VERSION ""

NS_ :

BS_:

BU_: XXX

BO_ 85 EPB: 8 XXX
 SG_ EPB_ACTIVE : 40|1@1+ (1,0) [0|1] "" XXX

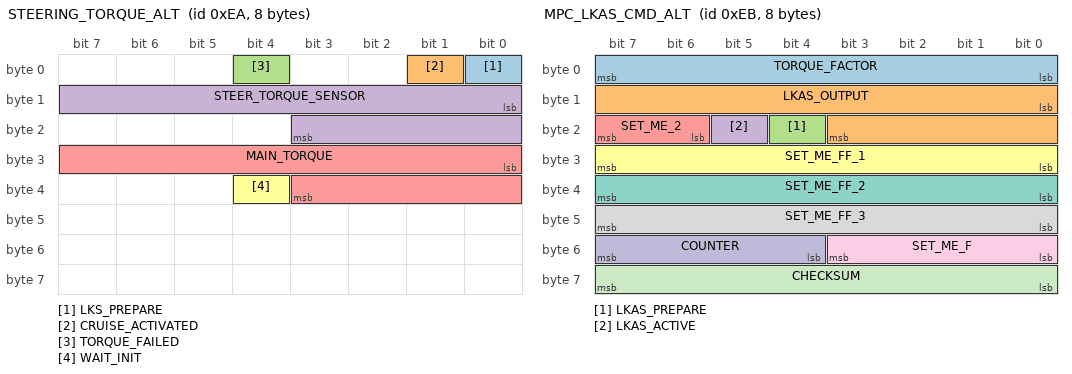
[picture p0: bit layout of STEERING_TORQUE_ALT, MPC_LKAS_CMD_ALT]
BO_ 234 STEERING_TORQUE_ALT: 8 XXX
 SG_ LKS_PREPARE : 0|1@1+ (1,0) [0|1] "" XXX
 SG_ CRUISE_ACTIVATED : 1|1@1+ (1,0) [0|1] "" XXX
 SG_ TORQUE_FAILED : 4|1@1+ (1,0) [0|1] "" XXX
 SG_ STEER_TORQUE_SENSOR : 8|12@1- (1,0) [0|4095] "" XXX
 SG_ MAIN_TORQUE : 24|12@1+ (0.15,-316) [0|4095] "" XXX
 SG_ WAIT_INIT : 36|1@1+ (1,0) [0|1] "" XXX

BO_ 235 MPC_LKAS_CMD_ALT: 8 XXX
 SG_ TORQUE_FACTOR : 0|8@1+ (1,0) [0|255] "" XXX
 SG_ LKAS_OUTPUT : 8|12@1- (0.15,0) [0|4095] "" XXX
 SG_ LKAS_PREPARE : 20|1@1+ (1,0) [0|1] "" XXX
 SG_ LKAS_ACTIVE : 21|1@1+ (1,0) [0|1] "" XXX
 SG_ SET_ME_2 : 22|2@1+ (1,0) [0|1] "" XXX
 SG_ SET_ME_FF_1 : 24|8@1+ (1,0) [0|255] "" XXX
 SG_ SET_ME_FF_2 : 32|8@1+ (1,0) [0|255] "" XXX
 SG_ SET_ME_FF_3 : 40|8@1+ (1,0) [0|255] "" XXX
 SG_ SET_ME_F : 48|4@1+ (1,0) [0|15] "" XXX
 SG_ COUNTER : 55|4@0+ (1,0) [0|15] "" XXX
 SG_ CHECKSUM : 63|8@0+ (1,0) [0|255] "" XXX

BO_ 269 ECM: 8 XXX
 SG_ ENG_RPM : 0|16@1+ (0.25,0) [0|255] "" XXX
 SG_ GAS_PEDAL : 40|8@1+ (0.00392,0) [0|255] "" XXX

/* DRIVER_EPS_TORQUE could just be STEER_RATE */
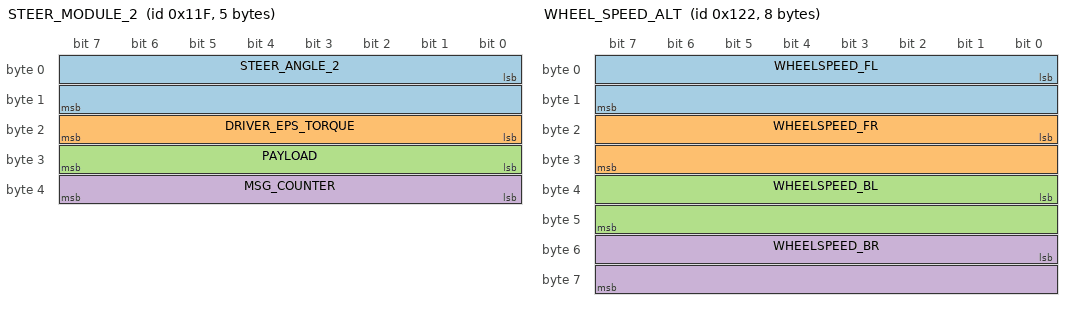
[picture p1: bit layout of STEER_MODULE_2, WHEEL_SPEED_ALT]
BO_ 287 STEER_MODULE_2: 5 XXX
 SG_ STEER_ANGLE_2 : 0|16@1- (0.1,0) [0|65535] "" XXX
 SG_ DRIVER_EPS_TORQUE : 16|8@1+ (1,0) [0|255] "" XXX
 SG_ PAYLOAD : 24|8@1+ (1,0) [0|255] "" XXX
 SG_ MSG_COUNTER : 32|8@1+ (1,0) [0|255] "" XXX

BO_ 289 ESC: 8 XXX
 SG_ VEHICLE_SPEED : 0|12@1+ (0.0725,0) [0|4095] "" XXX

BO_ 290 WHEEL_SPEED_ALT: 8 XXX
 SG_ WHEELSPEED_FL : 0|16@1+ (0.1,0) [0|65535] "" XXX
 SG_ WHEELSPEED_FR : 16|16@1+ (0.1,0) [0|65535] "" XXX
 SG_ WHEELSPEED_BL : 32|16@1+ (0.1,0) [0|65535] "" XXX
 SG_ WHEELSPEED_BR : 48|16@1+ (0.1,0) [0|65535] "" XXX

BO_ 291 IPB: 8 XXX
 SG_ BRAKE_PRESSED : 43|1@0+ (1,0) [0|1] "" XXX

BO_ 301 BRAKE_PRESSED: 8 XXX
 SG_ BRAKE_PRESSED : 8|1@1+ (1,0) [0|1] "" XXX

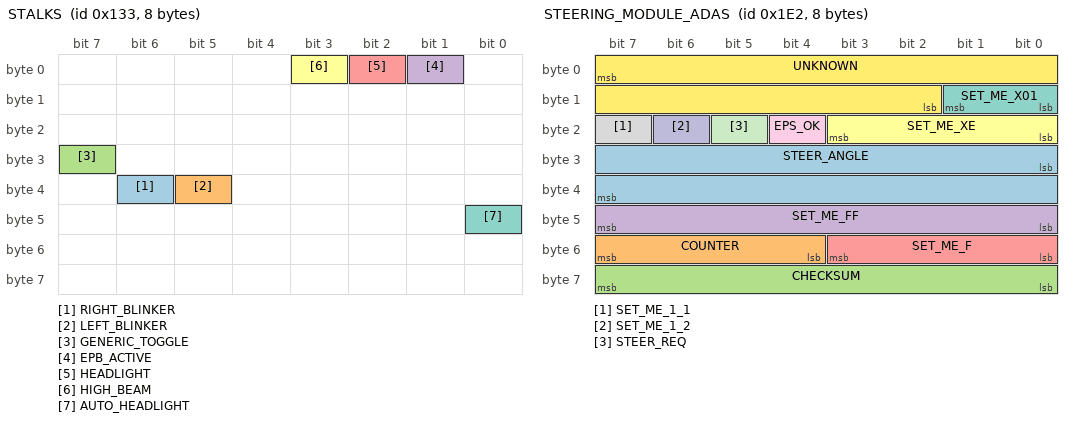
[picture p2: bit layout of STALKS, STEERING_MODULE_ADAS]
BO_ 307 STALKS: 8 XXX
 SG_ RIGHT_BLINKER : 38|1@0+ (1,0) [0|1] "" XXX
 SG_ LEFT_BLINKER : 37|1@0+ (1,0) [0|1] "" XXX
 SG_ GENERIC_TOGGLE : 31|1@0+ (1,0) [0|1] "" XXX
 SG_ EPB_ACTIVE : 1|1@1+ (1,0) [0|1] "" XXX
 SG_ HEADLIGHT : 2|1@1+ (1,0) [0|1] "" XXX
 SG_ HIGH_BEAM : 3|1@1+ (1,0) [0|1] "" XXX
 SG_ AUTO_HEADLIGHT : 40|1@0+ (1,0) [0|1] "" XXX

BO_ 482 STEERING_MODULE_ADAS: 8 XXX
 SG_ STEER_ANGLE : 24|16@1- (0.1,0) [0|255] "" XXX
 SG_ COUNTER : 55|4@0+ (1,0) [0|15] "" XXX
 SG_ CHECKSUM : 63|8@0+ (1,0) [0|255] "" XXX
 SG_ SET_ME_FF : 47|8@0+ (1,0) [0|255] "" XXX
 SG_ SET_ME_F : 48|4@1+ (1,0) [0|15] "" XXX
 SG_ SET_ME_XE : 16|4@1+ (1,0) [0|15] "" XXX
 SG_ SET_ME_X01 : 8|2@1+ (1,0) [0|3] "" XXX
 SG_ SET_ME_1_1 : 23|1@0+ (1,0) [0|1] "" XXX
 SG_ EPS_OK : 20|1@0+ (1,0) [0|1] "" XXX
 SG_ SET_ME_1_2 : 22|1@0+ (1,0) [0|3] "" XXX
 SG_ STEER_REQ : 21|1@0+ (1,0) [0|1] "" XXX
 SG_ UNKNOWN : 7|14@0- (1,0) [0|65535] "" XXX

BO_ 455 STEER_ANGLE_ALT: 8 XXX
 SG_ STEER_ANGLE : 0|16@1- (0.1,0) [0|4095] "" XXX
 SG_ STEER_RATE : 16|8@1+ (4,0) [0|255] "" XXX

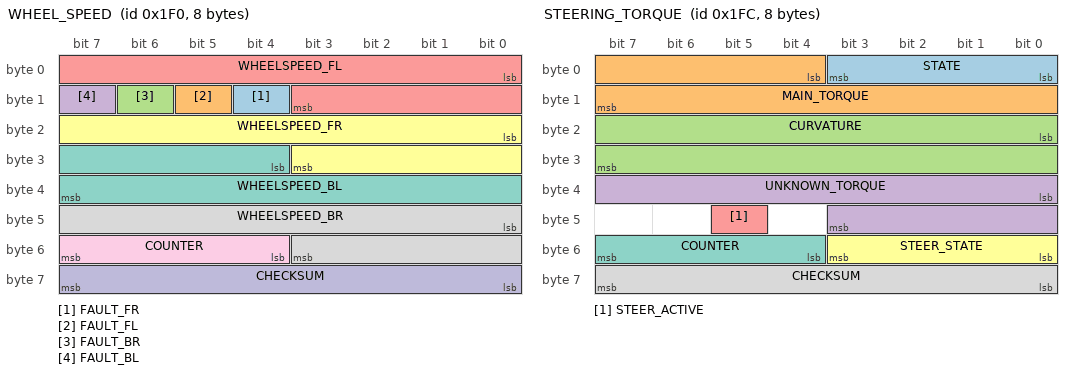
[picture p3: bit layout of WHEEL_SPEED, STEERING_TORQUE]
BO_ 496 WHEEL_SPEED: 8 XXX
 SG_ FAULT_FR : 12|1@1+ (1,0) [0|1] "" XXX
 SG_ FAULT_FL : 13|1@1+ (1,0) [0|1] "" XXX
 SG_ FAULT_BR : 14|1@1+ (1,0) [0|1] "" XXX
 SG_ FAULT_BL : 15|1@1+ (1,0) [0|1] "" XXX
 SG_ WHEELSPEED_FL : 0|12@1+ (0.1,0) [0|281.4625] "km/h" XXX
 SG_ WHEELSPEED_FR : 16|12@1+ (0.1,0) [0|281.4625] "km/h" XXX
 SG_ WHEELSPEED_BL : 28|12@1+ (0.1,0) [0|281.4625] "km/h" XXX
 SG_ WHEELSPEED_BR : 40|12@1+ (0.1,0) [0|281.4625] "km/h" XXX
 SG_ COUNTER : 55|4@0+ (1,0) [0|15] "" XXX
 SG_ CHECKSUM : 63|8@0+ (1,0) [0|255] "" XXX

BO_ 508 STEERING_TORQUE: 8 XXX
 SG_ STATE : 0|4@1+ (1,0) [0|15] "" XXX
 SG_ MAIN_TORQUE : 4|12@1- (0.1,0) [0|15] "Nm" XXX
 SG_ CURVATURE : 16|16@1- (0.1,0) [0|65535] "" XXX
 SG_ UNKNOWN_TORQUE : 32|12@1- (1,0) [0|255] "" XXX
 SG_ STEER_ACTIVE : 45|1@1+ (1,0) [0|1] "" XXX
 SG_ STEER_STATE : 51|4@0+ (1,0) [0|1] "" XXX
 SG_ COUNTER : 55|4@0+ (1,0) [0|15] "" XXX
 SG_ CHECKSUM : 63|8@0+ (1,0) [0|255] "" XXX

BO_ 522 ENGINE_RPM: 8 XXX
 SG_ ENG_RPM : 31|8@0+ (1,0) [0|255] "" XXX

BO_ 523 ENGINE_GAUGE: 8 XXX
 SG_ ENG_RPM : 15|8@0+ (12,0) [0|0] "" XXX

BO_ 536 EPB_NG: 8 XXX
 SG_ EPB_ACTIVE : 0|2@1+ (1,0) [0|3] "" XXX
 SG_ EPB_STATUS : 9|3@1+ (1,0) [0|7] "" XXX

BO_ 544 PEDAL_PRESSED: 8 XXX
 SG_ PEDAL_PRESSED_ACTIVE_LOW : 12|1@0+ (1,0) [0|1] "" XXX

BO_ 546 YAW_SENSOR: 8 XXX
 SG_ YAW_RATE : 0|12@1+ (0.002132603,-2.094216146) [0|4095] "" XXX
 SG_ YAW_OFFSET : 12|12@1+ (0.002132603,-0.130088783) [0|4095] "" XXX

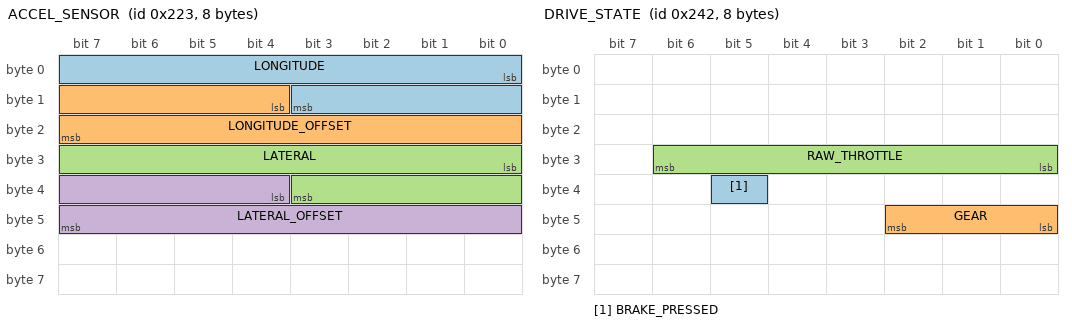
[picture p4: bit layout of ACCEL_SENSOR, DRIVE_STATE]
BO_ 547 ACCEL_SENSOR: 8 XXX
 SG_ LONGITUDE : 0|12@1- (0.027126736,-21.592881856) [-2848|1247] "" XXX
 SG_ LONGITUDE_OFFSET : 12|12@1+ (0.027126736,-21.592881856) [0|4095] "" XXX
 SG_ LATERAL : 24|12@1- (0.027126736,-21.592881856) [-2848|1247] "" XXX
 SG_ LATERAL_OFFSET : 36|12@1+ (0.027126736,-21.592881856) [0|4095] "" XXX

BO_ 578 DRIVE_STATE: 8 XXX
 SG_ BRAKE_PRESSED : 37|1@0+ (1,0) [0|1] "" XXX
 SG_ GEAR : 40|3@1+ (1,0) [0|7] "" XXX
 SG_ RAW_THROTTLE : 30|7@0+ (1,0) [0|127] "" XXX

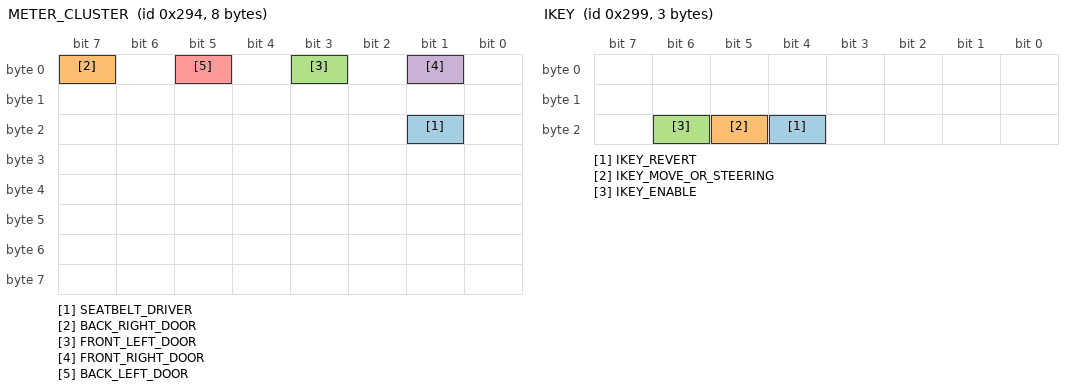
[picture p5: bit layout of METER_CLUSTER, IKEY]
BO_ 660 METER_CLUSTER: 8 XXX
 SG_ SEATBELT_DRIVER : 17|1@0+ (1,0) [0|1] "" XXX
 SG_ BACK_RIGHT_DOOR : 7|1@0+ (1,0) [0|1] "" XXX
 SG_ FRONT_LEFT_DOOR : 3|1@0+ (1,0) [0|1] "" XXX
 SG_ FRONT_RIGHT_DOOR : 1|1@1+ (1,0) [0|511] "" XXX
 SG_ BACK_LEFT_DOOR : 5|1@1+ (1,0) [0|511] "" XXX

BO_ 665 IKEY: 3 XXX
 SG_ IKEY_REVERT : 20|1@1+ (1,0) [0|1] "" XXX
 SG_ IKEY_MOVE_OR_STEERING : 21|1@1+ (1,0) [0|1] "" XXX
 SG_ IKEY_ENABLE : 22|1@1+ (1,0) [0|1] "" XXX

BO_ 790 LKAS_HUD_ADAS: 8 XXX
CM_ BO_ 790 "Openpilot code packs continuous SET_ME_XFF + TSR_STATUS into one lkas_hud_status_passthrough chunk in BYD carstate/controller.";
 SG_ HMA : 4|5@0+ (1,0) [0|7] "" XXX
 SG_ LEFT_LANE_VISIBLE : 5|1@0+ (1,0) [0|1] "" XXX
 SG_ LSS_STATE : 7|2@0+ (1,0) [0|1] "" XXX
 SG_ PT3 : 8|2@1+ (1,0) [0|3] "" XXX
 SG_ HAND_ON_WHEEL_WARNING : 10|1@0+ (1,0) [0|1] "" XXX
 SG_ PT2 : 11|5@1+ (1,0) [0|31] "" XXX
 SG_ SET_ME_XFF : 23|8@0+ (1,0) [0|255] "" XXX
 SG_ TSR_STATUS : 31|3@0+ (1,0) [0|7] "" XXX
 SG_ SET_ME_1_2 : 32|1@0+ (1,0) [0|1] "" XXX
 SG_ PT5 : 33|2@1+ (1,0) [0|3] "" XXX
 SG_ RIGHT_LANE_VISIBLE : 35|1@0+ (1,0) [0|1] "" XXX
 SG_ STEER_ACTIVE_ACTIVE_LOW : 36|1@0+ (1,0) [0|1] "" XXX
 SG_ LKAS_ENABLED : 37|1@0+ (1,0) [0|1] "" XXX
 SG_ PT4 : 39|2@0+ (1,0) [0|3] "" XXX
 SG_ TSR : 47|8@0+ (1,0) [0|255] "" XXX
 SG_ SETTINGS : 48|4@1+ (1,0) [0|15] "" XXX
 SG_ COUNTER : 55|4@0+ (1,0) [0|15] "" XXX
 SG_ CHECKSUM : 63|8@0+ (1,0) [0|255] "" XXX

BO_ 813 ACC_HUD_ADAS: 8 XXX
 SG_ SET_SPEED : 0|9@1+ (0.5,0) [0|255.5] "" XXX
 SG_ HAS_LEAD : 9|1@1+ (1,0) [0|1] "" XXX
 SG_ SET_DISTANCE : 10|3@1+ (1,0) [0|7] "" XXX
 SG_ LEAD_DISTANCE : 13|3@1+ (1,0) [0|7] "" XXX
 SG_ AEB : 16|1@1+ (1,0) [0|1] "" XXX
 SG_ FCW : 17|1@1+ (1,0) [0|1] "" XXX
 SG_ SET_ME_1 : 18|1@1+ (1,0) [0|1] "" XXX
 SG_ ACC_ON2 : 19|1@0+ (1,0) [0|1] "" XXX
 SG_ ACC_CONTROLLABLE_AND_ON : 20|1@1+ (1,0) [0|1] "" XXX
 SG_ OVERRIDE : 21|1@1+ (1,0) [0|1] "" XXX
 SG_ ACC_ON1 : 22|1@0+ (1,0) [0|1] "" XXX
 SG_ TOO_CLOSE : 23|1@0+ (1,0) [0|1] "" XXX
 SG_ SET_ME_1_1 : 24|3@1+ (1,0) [0|1] "" XXX
 SG_ NOTIFY : 27|5@1+ (1,0) [0|127] "" XXX
 SG_ ERROR : 32|4@1+ (1,0) [0|15] "" XXX
 SG_ SET_ME_XFF : 36|8@1+ (1,0) [0|4095] "" XXX
 SG_ CRUISE_STATE : 44|4@1+ (1,0) [0|15] "" XXX
 SG_ SET_ME_XF : 55|4@0+ (1,0) [0|15] "" XXX
 SG_ COUNTER : 51|4@0+ (1,0) [0|15] "" XXX
 SG_ CHECKSUM : 63|8@0+ (1,0) [0|255] "" XXX

BO_ 814 ACC_CMD: 8 XXX
 SG_ ACCEL_CMD : 0|8@1+ (0.05,-5) [-5|7.75] "m/s2" XXX
 SG_ COUNTER : 51|4@0+ (1,0) [0|15] "" XXX
 SG_ CHECKSUM : 63|8@0+ (1,0) [0|255] "" XXX
 SG_ SET_ME_25_1 : 10|6@1+ (1,0) [0|255] "" XXX
 SG_ SET_ME_25_2 : 18|6@1+ (1,0) [0|255] "" XXX
 SG_ ACC_ON_1 : 9|1@0+ (1,0) [0|1] "" XXX
 SG_ ACC_ON_2 : 17|1@0+ (1,0) [0|1] "" XXX
 SG_ SET_ME_XF : 55|4@0+ (1,0) [0|15] "" XXX
 SG_ ACC_OVERRIDE_OR_STANDSTILL : 45|1@0+ (1,0) [0|1] "" XXX
 SG_ ACC_CONTROLLABLE_AND_ON : 44|1@0+ (1,0) [0|1] "" XXX
 SG_ STANDSTILL_STATE : 40|1@0+ (1,0) [0|1] "" XXX
 SG_ SET_ME_X8 : 31|4@0+ (1,0) [0|255] "" XXX
 SG_ CMD_REQ_ACTIVE_LOW : 36|1@0+ (1,0) [0|255] "" XXX
 SG_ ACC_REQ_NOT_STANDSTILL : 43|1@0+ (1,0) [0|1] "" XXX
 SG_ STANDSTILL_RESUME : 39|1@0+ (1,0) [0|1] "" XXX
 SG_ SET_ME_1 : 38|1@0+ (1,0) [0|1] "" XXX
 SG_ ACCEL_FACTOR : 32|4@1+ (1,0) [0|15] "" XXX
 SG_ DECEL_FACTOR : 24|4@1+ (1,0) [0|15] "" XXX
 SG_ ENGAGE_BIT : 47|1@0+ (1,0) [0|1] "" XXX

BO_ 815 ACC_AEB: 8 XXX
 SG_ PAYLOAD : 0|48@1+ (1,0) [0|4.5035996273705e+15] "" XXX
 SG_ SETME_0xF : 55|4@0+ (1,0) [0|15] "" XXX

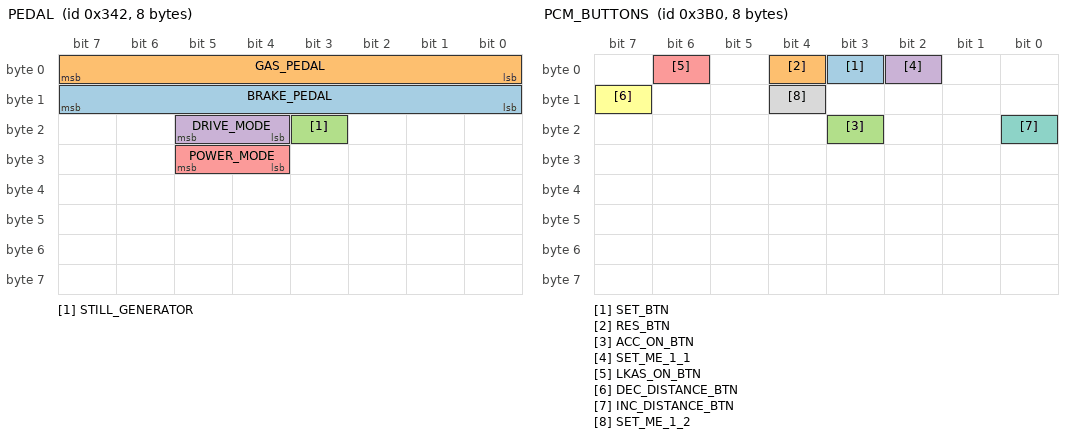
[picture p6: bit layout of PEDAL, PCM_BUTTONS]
BO_ 834 PEDAL: 8 XXX
 SG_ BRAKE_PEDAL : 8|8@1+ (0.01,0) [0|255] "" XXX
 SG_ GAS_PEDAL : 0|8@1+ (0.01,0) [0|255] "" XXX
 SG_ STILL_GENERATOR : 19|1@1+ (1,0) [0|1] "" XXX
 SG_ DRIVE_MODE : 20|2@1+ (1,0) [0|255] "" XXX
 SG_ POWER_MODE : 28|2@1+ (1,0) [0|1] "" XXX

BO_ 926 GAUGE_SPEED: 8 XXX
 SG_ GAUGE_SPEED : 8|8@1+ (1,0) [0|255] "" XXX

BO_ 944 PCM_BUTTONS: 8 XXX
 SG_ SET_BTN : 3|1@0+ (1,0) [0|1] "" XXX
 SG_ RES_BTN : 4|1@0+ (1,0) [0|1] "" XXX
 SG_ ACC_ON_BTN : 19|1@0+ (1,0) [0|1] "" XXX
 SG_ SET_ME_1_1 : 2|1@0+ (1,0) [0|1] "" XXX
 SG_ LKAS_ON_BTN : 6|1@0+ (1,0) [0|1] "" XXX
 SG_ DEC_DISTANCE_BTN : 15|1@0+ (1,0) [0|1] "" XXX
 SG_ INC_DISTANCE_BTN : 16|1@0+ (1,0) [0|1] "" XXX
 SG_ SET_ME_1_2 : 12|1@0+ (1,0) [0|1] "" XXX

BO_ 1048 BSM: 8 XXX
 SG_ LEFT_APPROACH : 23|1@0+ (1,0) [0|1] "" XXX
 SG_ RIGHT_APPROACH : 17|1@0+ (1,0) [0|1] "" XXX

BO_ 692 ADAS2: 8 XXX

BO_ 843 ADAS4: 8 XXX

BO_ 1074 ADAS6: 8 XXX

/* USED BY OTHER BYDs */
BO_ 848 RADAR_UNUSED_0: 8 XXX

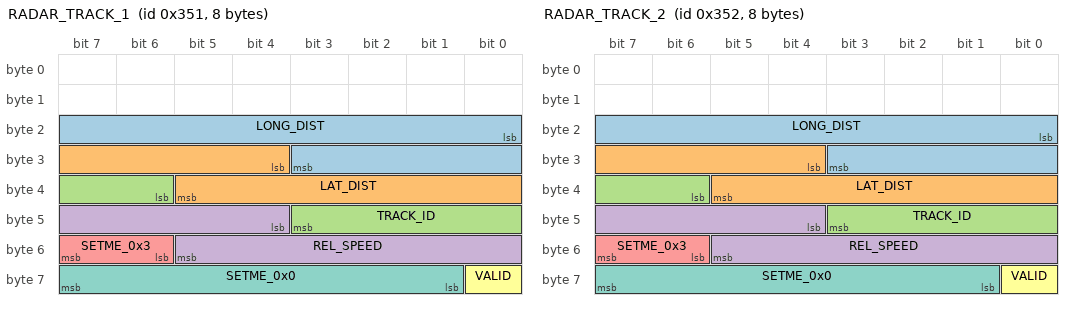
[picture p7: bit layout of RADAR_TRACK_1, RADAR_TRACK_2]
BO_ 849 RADAR_TRACK_1: 8 XXX
 SG_ LONG_DIST : 16|12@1- (0.06,-4) [-61.44|61.41] "m" XXX
 SG_ LAT_DIST : 28|10@1+ (0.05,-25.6) [-15.36|15.33] "m" XXX
 SG_ TRACK_ID : 38|6@1+ (1,0) [0|63] "" XXX
 SG_ REL_SPEED : 44|10@1+ (1,-512) [-512|511] "km/s" XXX
 SG_ SETME_0x3 : 54|2@1+ (1,0) [0|3] "" XXX
 SG_ VALID : 56|1@0+ (1,0) [0|1] "" XXX
 SG_ SETME_0x0 : 57|7@1+ (1,0) [0|127] "" XXX

BO_ 850 RADAR_TRACK_2: 8 XXX
 SG_ LONG_DIST : 16|12@1- (0.06,-4) [-61.44|61.41] "m" XXX
 SG_ LAT_DIST : 28|10@1+ (-0.05,-25.6) [-15.36|15.33] "m" XXX
 SG_ TRACK_ID : 38|6@1+ (1,0) [0|63] "" XXX
 SG_ REL_SPEED : 44|10@1+ (1,-512) [-512|511] "km/s" XXX
 SG_ SETME_0x3 : 54|2@1+ (1,0) [0|3] "" XXX
 SG_ VALID : 56|1@0+ (1,0) [0|1] "" XXX
 SG_ SETME_0x0 : 57|7@1+ (1,0) [0|127] "" XXX

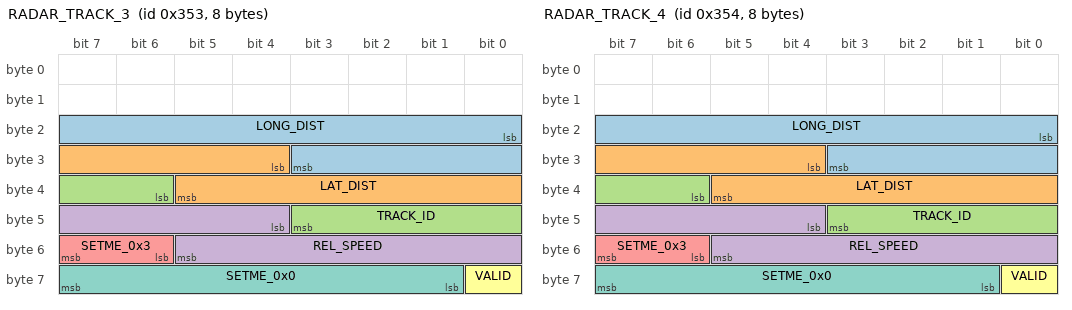
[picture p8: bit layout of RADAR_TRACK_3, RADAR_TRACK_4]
BO_ 851 RADAR_TRACK_3: 8 XXX
 SG_ LONG_DIST : 16|12@1- (0.06,-4) [-61.44|61.41] "m" XXX
 SG_ LAT_DIST : 28|10@1+ (0.05,-25.6) [-15.36|15.33] "m" XXX
 SG_ TRACK_ID : 38|6@1+ (1,0) [0|63] "" XXX
 SG_ REL_SPEED : 44|10@1+ (1,-512) [-512|511] "km/s" XXX
 SG_ SETME_0x3 : 54|2@1+ (1,0) [0|3] "" XXX
 SG_ VALID : 56|1@0+ (1,0) [0|1] "" XXX
 SG_ SETME_0x0 : 57|7@1+ (1,0) [0|127] "" XXX

BO_ 852 RADAR_TRACK_4: 8 XXX
 SG_ LONG_DIST : 16|12@1- (0.06,-4) [-61.44|61.41] "m" XXX
 SG_ LAT_DIST : 28|10@1+ (0.05,-25.6) [-15.36|15.33] "m" XXX
 SG_ TRACK_ID : 38|6@1+ (1,0) [0|63] "" XXX
 SG_ REL_SPEED : 44|10@1+ (1,-512) [-512|511] "km/s" XXX
 SG_ SETME_0x3 : 54|2@1+ (1,0) [0|3] "" XXX
 SG_ VALID : 56|1@0+ (1,0) [0|1] "" XXX
 SG_ SETME_0x0 : 57|7@1+ (1,0) [0|127] "" XXX

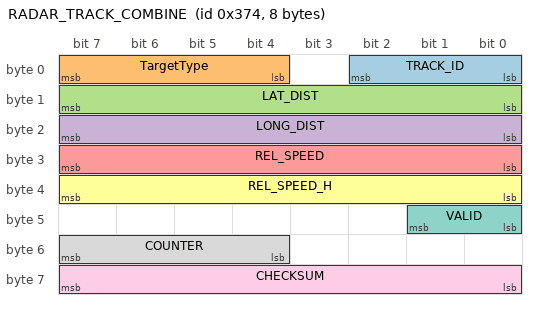
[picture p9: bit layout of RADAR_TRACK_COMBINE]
BO_ 884 RADAR_TRACK_COMBINE: 8 XXX
 SG_ TRACK_ID : 0|3@1+ (1,0) [0|7] "bit" XXX
 SG_ TargetType : 4|4@1+ (1,0) [0|8] "bit" XXX
 SG_ LAT_DIST : 8|8@1+ (0.1,-12) [-100|100] "bit" XXX
 SG_ LONG_DIST : 16|8@1+ (1,-100) [-100|100] "bit" XXX
 SG_ REL_SPEED : 24|8@1+ (1,0) [0|254] "km/h" XXX
 SG_ REL_SPEED_H : 32|8@1+ (1,0) [0|254] "km/h" XXX
 SG_ VALID : 40|2@1+ (1,0) [0|3] "bit" XXX
 SG_ COUNTER : 55|4@0+ (1,0) [0|15] "" XXX
 SG_ CHECKSUM : 63|8@0+ (1,0) [0|255] "" XXX

VAL_ 578 GEAR 4 "D" 2 "R" 1 "P" ;
VAL_ 813 SET_DISTANCE 8 "4bar" 4 "3bar" 2 "2bar" 1 "1bar" ;
VAL_ 813 NOTIFY 4 "OVERRIDE" 3 "ENGAGE" 2 "DISENGAGE" 7 "ACC_ON" 8 "ACC_OFF" 0 "NONE";
VAL_ 813 CRUISE_STATE 0 "OFF" 1 "Passive" 2 "StandBy" 3 "Active" 4 "BrakeOnly" 5 "Override" 6 "StandStillActive" 7 "StandStillWait" 8 "Failure" 9 "PermanentFailure";

CM_ SG_ 482 EPS_OK "Crosscheck 2026-08 vs qzwf/opendbc's independent RE of this same message (STEERING_MODULE_ADAS, bit 20): qzwf calls this bit STEER_REQ_ACTIVE_LOW (an inverse mirror of STEER_REQ at bit 21), not an EPS health flag. Every other signal in this message (STEER_ANGLE, COUNTER, CHECKSUM, STEER_REQ, and all SET_ME_* constants) matches qzwf's layout bit-for-bit. This bit feeds lkas_healthy in opendbc/car/byd/cam_lka/carstate.py - unresolved without a local capture, not changed here. See docs/BYD_ATTO3_COMMUNITY_LINEAGE.md.";
CM_ SG_ 814 ACCEL_CMD "CORRECTED 2026-09-21: was (1,-100) raw, with opendbc/car/byd/values.py applying ACCEL_MULT=26 on top, which put 1.30x the requested acceleration on the wire. Now carries the capture-derived scale directly, matching BYD_Atto3/DBC/byd_atto3.dbc's MPC_AccelerationCmd (0|8, x0.05, -5). Evidence: create_accel_command's +30 raw-count clip decodes to exactly +1.50 m/s2, the ceiling BYD_Atto3's COMMA-device captures recorded, and -80 to exactly -4.00; BYD_Atto3/DOC/jerk_brake_summary.md finds comfort/jerk values in 0.05 steps across every capture. qzwf/opendbc uses a third value (x16.67) and explicitly disclaims it as inferred, keeping ACC_CMD out of its TX allowlist. Raw TX envelope unchanged (raw 20..130); bench-validate before hardware use. See docs/BYD_ATTO3_QZWF_REFERENCE_PORT.md.";
CM_ BO_ 496 "DISPUTED 2026-09-21: this fork decodes WHEEL_SPEED as four 12-bit wheels at x0.1 plus fault bits 12-15. Two independent lineages decode the same frame as a SINGLE 16-bit speed at 0|16@1+ - BYD_Atto3/DBC/byd_atto3.dbc's ESP_VehicleSpeed (x1/14 km/h per count, from local CANape captures) and qzwf/opendbc's WHEELSPEED_CLEAN (x0.1, unused by their carstate). qzwf reads per-wheel speed from 0x122 instead and corrects x0.1 by 40/53 after measuring raw values ~32.5% high against the odometer, landing on 0.0755 - within 5.7% of byd_atto3.dbc's 1/14 = 0.0714, and both well below the x0.1 used here. carstate.parse_wheel_speeds, radar_interface and safety/modes/byd.h's UPDATE_VEHICLE_SPEED all read this frame, so vEgo and the speed the angle-rate lookup interpolates against are affected. Unresolved without a local GPS or odometer run - structure and scale both unchanged here pending one.";
CM_ SG_ 290 WHEELSPEED_BR "CROSSCHECK 2026-09-21: qzwf/opendbc declares this field identically (48|16@1+ x0.1) and then measured that it is wrong - 'byte 7 is a constant status byte (0x41), NOT the high byte of the wheel speed' - and derives rear-right from the other three wheels instead. Nothing in this fork reads WHEEL_SPEED_ALT today. Left as-is pending a local capture rather than guessing the real width. See docs/BYD_ATTO3_QZWF_REFERENCE_PORT.md.";
CM_ SG_ 790 SET_ME_XFF "DISPUTED 2026-09-21: bits 16-23 are not a constant. byd_han_dmev_2020.dbc (same address, ACC_MPC_STATE) and BYD_Atto3/DBC/byd_atto3.dbc both place a signed 11-bit LKAS_Output / MPC_LkasOutput at 16|11 here, with LKAS_ReqPrepare at 27 and LKAS_Active at 28 - and safety/modes/byd.h's mpc_lka path decodes exactly those bits as desired_torque. cam_lka/carstate.py reads this byte into lkas_hud_status_passthrough and create_lkas_hud writes it back out, so this fork is round-tripping the low byte of the camera's LKA torque output as filler. byd_atto3.dbc's CM_ SG_ 482 CONST_0xFF_B5 records qzwf/opendbc finding that treating a camera-derived field in the steering frame as don't-care silently killed their car's stock ADAS. qzwf's own 0x316 defines nothing in this region, so this is unresolved - not changed here.";
CM_ SG_ 482 UNKNOWN "CROSSCHECK 2026-09-21: this 14-bit field plus SET_ME_X01 and SET_ME_XE cover bits 0-19, which BYD_Atto3/DBC/byd_atto3.dbc decodes as two signed 10-bit steering angle-rate limits (MPC_SteerAngleRateUpper 0|10, MPC_SteerAngleRateLower 10|10). Decoding what create_can_steer_command actually transmits through that layout gives +299/-299 with SET_ME_XE=0xB and +299/-107 with 0xE, which also explains this file's own note that 0xB 'seem[s] to have the highest angle limit at high speed'. Independently, qzwf/opendbc measured the camera holding bytes 0-2 at 2b 55 eb - i.e. exactly the 0xB triple - for 1111 of 1121 STEER_REQ frames AT EVERY SPEED, and documents that varying these fields dropped the car's entire stock ADAS after tens of seconds. The 0xE-at-standstill variant in cam_lka/bydcan.py therefore puts a triple on the wire that no capture has seen; verify against a local capture before keeping it.";
